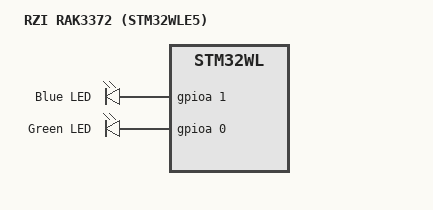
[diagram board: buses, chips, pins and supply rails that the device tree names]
/* SPDX-License-Identifier: Apache-2.0 */
/*
 * Product board for the RAK3372 WisBlock Core (RAK3172 stamp module).
 * Radio is the STM32WLE5 on-chip SUBGHZ (st,stm32wl-subghz-radio), not an
 * SPI SX1262 shield. USP support is the RAK3372 west patch in
 * zephyr/patches/usp_zephyr. Single-slot flash: no FUOTA.
 */

/dts-v1/;
#include <rakwireless/rzi_rak3172.dtsi>
#include <zephyr/dt-bindings/gpio/gpio.h>
#include "rzi_rak3372-partitions.dtsi"

/ {
	model = "RZI RAK3372 (STM32WLE5)";
	compatible = "rakwireless,rzi-rak3372-stm32wl";

	chosen {
		zephyr,console = &usart1;
		zephyr,shell-uart = &usart1;
		zephyr,system-timer = &lptim1;
		zephyr,lorawan-transceiver = &lora;
	};

	leds {
		compatible = "gpio-leds";

		blue_led: led_2 {
			gpios = <&gpioa 1 GPIO_ACTIVE_HIGH>;
			label = "Blue LED";
		};

		green_led: led_1 {
			gpios = <&gpioa 0 GPIO_ACTIVE_HIGH>;
			label = "Green LED";
		};
	};

	aliases {
		led0 = &green_led;
		lora0 = &lora;
		watchdog0 = &iwdg;
	};
};
